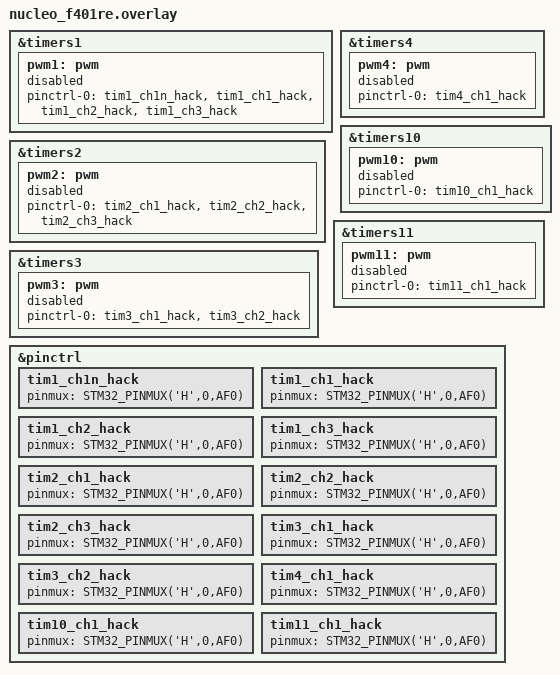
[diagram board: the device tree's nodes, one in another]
/*
 * Copyright (c) 2023 TiaC Systems
 * SPDX-License-Identifier: Apache-2.0
 */

#include "arduino_to_grove_if.dtsi"

/*
 * On ST Nucleo F401RE following pins can be used as PWM outputs:
 *
 *   Grove pin   port   timer   channel   Arduino UNO R3 requirements
 *
 *         D0    PA3                      RX   / GPIO
 *         D1    PA2                      TX   / GPIO
 *         D2    PA10   TIM1    CH3       INT0 / GPIO
 *   (SWO) D3    PB3    TIM2    CH2       INT1 / GPIO with PWM support
 *         D4    PB5                             GPIO
 *         D5    PB4    TIM3    CH1              GPIO with PWM support
 *         D6    PB10   TIM2    CH3              GPIO with PWM support
 *         D7    PA8    TIM1    CH1              GPIO
 *         D8    PA9    TIM1    CH2              GPIO
 *         D9    PC7    TIM3    CH2              GPIO with PWM support
 *         D10   PB6    TIM4    CH1       SS   / GPIO with PWM support
 *         D11   PA7    TIM1    CH1N      MOSI / GPIO with PWM support
 *         D12   PA6                      MISO / GPIO
 *   (LD2) D13   PA5    TIM2    CH1       SCK  / GPIO
 *         D18   PB9    TIM11   CH1       SDA  / GPIO
 *         D19   PB8    TIM10   CH1       SCL  / GPIO
 */

&timers1 {
	pwm1: pwm {
		status = "disabled";
		pinctrl-0 = <&tim1_ch1n_hack
			     &tim1_ch1_hack
			     &tim1_ch2_hack
			     &tim1_ch3_hack>;
		pinctrl-names = "default";
	};
};

#undef GROVE_PWM_D11_SLOW
#define GROVE_PWM_D11_SLOW				\
	&timers1 {					\
		st,prescaler = <10000>;			\
	};

#undef GROVE_PWM_D11_ENABLE
#define GROVE_PWM_D11_ENABLE				\
	&pwm1 {						\
		status = "okay";			\
	};

#undef GROVE_PWM_D11_PINCTRL
#define GROVE_PWM_D11_PINCTRL				\
	/delete-node/ &tim1_ch1n_hack;			\
	tim1_ch1n_hack: &tim1_ch1n_pa7 {};

#undef GROVE_PWM_D7_SLOW
#define GROVE_PWM_D7_SLOW				\
	&timers1 {					\
		st,prescaler = <10000>;			\
	};

#undef GROVE_PWM_D7_ENABLE
#define GROVE_PWM_D7_ENABLE				\
	&pwm1 {						\
		status = "okay";			\
	};

#undef GROVE_PWM_D7_PINCTRL
#define GROVE_PWM_D7_PINCTRL				\
	/delete-node/ &tim1_ch1_hack;			\
	tim1_ch1_hack: &tim1_ch1_pa8 {};

#undef GROVE_PWM_D8_SLOW
#define GROVE_PWM_D8_SLOW				\
	&timers1 {					\
		st,prescaler = <10000>;			\
	};

#undef GROVE_PWM_D8_ENABLE
#define GROVE_PWM_D8_ENABLE				\
	&pwm1 {						\
		status = "okay";			\
	};

#undef GROVE_PWM_D8_PINCTRL
#define GROVE_PWM_D8_PINCTRL				\
	/delete-node/ &tim1_ch2_hack;			\
	tim1_ch2_hack: &tim1_ch2_pa9 {};

#undef GROVE_PWM_D2_SLOW
#define GROVE_PWM_D2_SLOW				\
	&timers1 {					\
		st,prescaler = <10000>;			\
	};

#undef GROVE_PWM_D2_ENABLE
#define GROVE_PWM_D2_ENABLE				\
	&pwm1 {						\
		status = "okay";			\
	};

#undef GROVE_PWM_D2_PINCTRL
#define GROVE_PWM_D2_PINCTRL				\
	/delete-node/ &tim1_ch3_hack;			\
	tim1_ch3_hack: &tim1_ch3_pa10 {};

&timers2 {
	pwm2: pwm {
		status = "disabled";
		pinctrl-0 = <&tim2_ch1_hack
			     &tim2_ch2_hack
			     &tim2_ch3_hack>;
		pinctrl-names = "default";
	};
};

#undef GROVE_PWM_D13_ENABLE
#define GROVE_PWM_D13_ENABLE				\
	&pwm2 {						\
		status = "okay";			\
	};

#undef GROVE_PWM_D13_PINCTRL
#define GROVE_PWM_D13_PINCTRL				\
	/delete-node/ &tim2_ch1_hack;			\
	tim2_ch1_hack: &tim2_ch1_pa5 {};

#undef GROVE_PWM_D3_ENABLE
#define GROVE_PWM_D3_ENABLE				\
	&pwm2 {						\
		status = "okay";			\
	};

#undef GROVE_PWM_D3_PINCTRL
#define GROVE_PWM_D3_PINCTRL				\
	/delete-node/ &tim2_ch2_hack;			\
	tim2_ch2_hack: &tim2_ch2_pb3 {};

#undef GROVE_PWM_D6_ENABLE
#define GROVE_PWM_D6_ENABLE				\
	&pwm2 {						\
		status = "okay";			\
	};

#undef GROVE_PWM_D6_PINCTRL
#define GROVE_PWM_D6_PINCTRL				\
	/delete-node/ &tim2_ch3_hack;			\
	tim2_ch3_hack: &tim2_ch3_pb10 {};

&timers3 {
	pwm3: pwm {
		status = "disabled";
		pinctrl-0 = <&tim3_ch1_hack
			     &tim3_ch2_hack>;
		pinctrl-names = "default";
	};
};

#undef GROVE_PWM_D5_SLOW
#define GROVE_PWM_D5_SLOW				\
	&timers3 {					\
		st,prescaler = <10000>;			\
	};

#undef GROVE_PWM_D5_ENABLE
#define GROVE_PWM_D5_ENABLE				\
	&pwm3 {						\
		status = "okay";			\
	};

#undef GROVE_PWM_D5_PINCTRL
#define GROVE_PWM_D5_PINCTRL				\
	/delete-node/ &tim3_ch1_hack;			\
	tim3_ch1_hack: &tim3_ch1_pb4 {};

#undef GROVE_PWM_D9_SLOW
#define GROVE_PWM_D9_SLOW				\
	&timers3 {					\
		st,prescaler = <10000>;			\
	};

#undef GROVE_PWM_D9_ENABLE
#define GROVE_PWM_D9_ENABLE				\
	&pwm3 {						\
		status = "okay";			\
	};

#undef GROVE_PWM_D9_PINCTRL
#define GROVE_PWM_D9_PINCTRL				\
	/delete-node/ &tim3_ch2_hack;			\
	tim3_ch2_hack: &tim3_ch2_pc7 {};

&timers4 {
	pwm4: pwm {
		status = "disabled";
		pinctrl-0 = <&tim4_ch1_hack>;
		pinctrl-names = "default";
	};
};

#undef GROVE_PWM_D10_SLOW
#define GROVE_PWM_D10_SLOW				\
	&timers4 {					\
		st,prescaler = <10000>;			\
	};

#undef GROVE_PWM_D10_ENABLE
#define GROVE_PWM_D10_ENABLE				\
	&pwm4 {						\
		status = "okay";			\
	};

#undef GROVE_PWM_D10_PINCTRL
#define GROVE_PWM_D10_PINCTRL				\
	/delete-node/ &tim4_ch1_hack;			\
	tim4_ch1_hack: &tim4_ch1_pb6 {};

&timers10 {
	pwm10: pwm {
		status = "disabled";
		pinctrl-0 = <&tim10_ch1_hack>;
		pinctrl-names = "default";
	};
};

#undef GROVE_PWM_D19_SLOW
#define GROVE_PWM_D19_SLOW				\
	&timers10 {					\
		st,prescaler = <10000>;			\
	};

#undef GROVE_PWM_D19_ENABLE
#define GROVE_PWM_D19_ENABLE				\
	&pwm10 {					\
		status = "okay";			\
	};

#undef GROVE_PWM_D19_PINCTRL
#define GROVE_PWM_D19_PINCTRL				\
	/delete-node/ &tim10_ch1_hack;			\
	tim10_ch1_hack: &tim10_ch1_pb8 {};

&timers11 {
	pwm11: pwm {
		status = "disabled";
		pinctrl-0 = <&tim11_ch1_hack>;
		pinctrl-names = "default";
	};
};

#undef GROVE_PWM_D18_SLOW
#define GROVE_PWM_D18_SLOW				\
	&timers11 {					\
		st,prescaler = <10000>;			\
	};

#undef GROVE_PWM_D18_ENABLE
#define GROVE_PWM_D18_ENABLE				\
	&pwm11 {					\
		status = "okay";			\
	};

#undef GROVE_PWM_D18_PINCTRL
#define GROVE_PWM_D18_PINCTRL				\
	/delete-node/ &tim11_ch1_hack;			\
	tim11_ch1_hack: &tim11_ch1_pb9 {};

#include <zephyr/dt-bindings/pinctrl/stm32-pinctrl.h>

&pinctrl {
	/* +++ hack +++ PH0-OSC_IN as AF0 --> SYS_AF +++ hack +++ */
	tim1_ch1n_hack: tim1_ch1n_hack { pinmux = <STM32_PINMUX('H',0,AF0)>; };
	tim1_ch1_hack: tim1_ch1_hack { pinmux = <STM32_PINMUX('H',0,AF0)>; };
	tim1_ch2_hack: tim1_ch2_hack { pinmux = <STM32_PINMUX('H',0,AF0)>; };
	tim1_ch3_hack: tim1_ch3_hack { pinmux = <STM32_PINMUX('H',0,AF0)>; };
	tim2_ch1_hack: tim2_ch1_hack { pinmux = <STM32_PINMUX('H',0,AF0)>; };
	tim2_ch2_hack: tim2_ch2_hack { pinmux = <STM32_PINMUX('H',0,AF0)>; };
	tim2_ch3_hack: tim2_ch3_hack { pinmux = <STM32_PINMUX('H',0,AF0)>; };
	tim3_ch1_hack: tim3_ch1_hack { pinmux = <STM32_PINMUX('H',0,AF0)>; };
	tim3_ch2_hack: tim3_ch2_hack { pinmux = <STM32_PINMUX('H',0,AF0)>; };
	tim4_ch1_hack: tim4_ch1_hack { pinmux = <STM32_PINMUX('H',0,AF0)>; };
	tim10_ch1_hack: tim10_ch1_hack { pinmux = <STM32_PINMUX('H',0,AF0)>; };
	tim11_ch1_hack: tim11_ch1_hack { pinmux = <STM32_PINMUX('H',0,AF0)>; };
};
